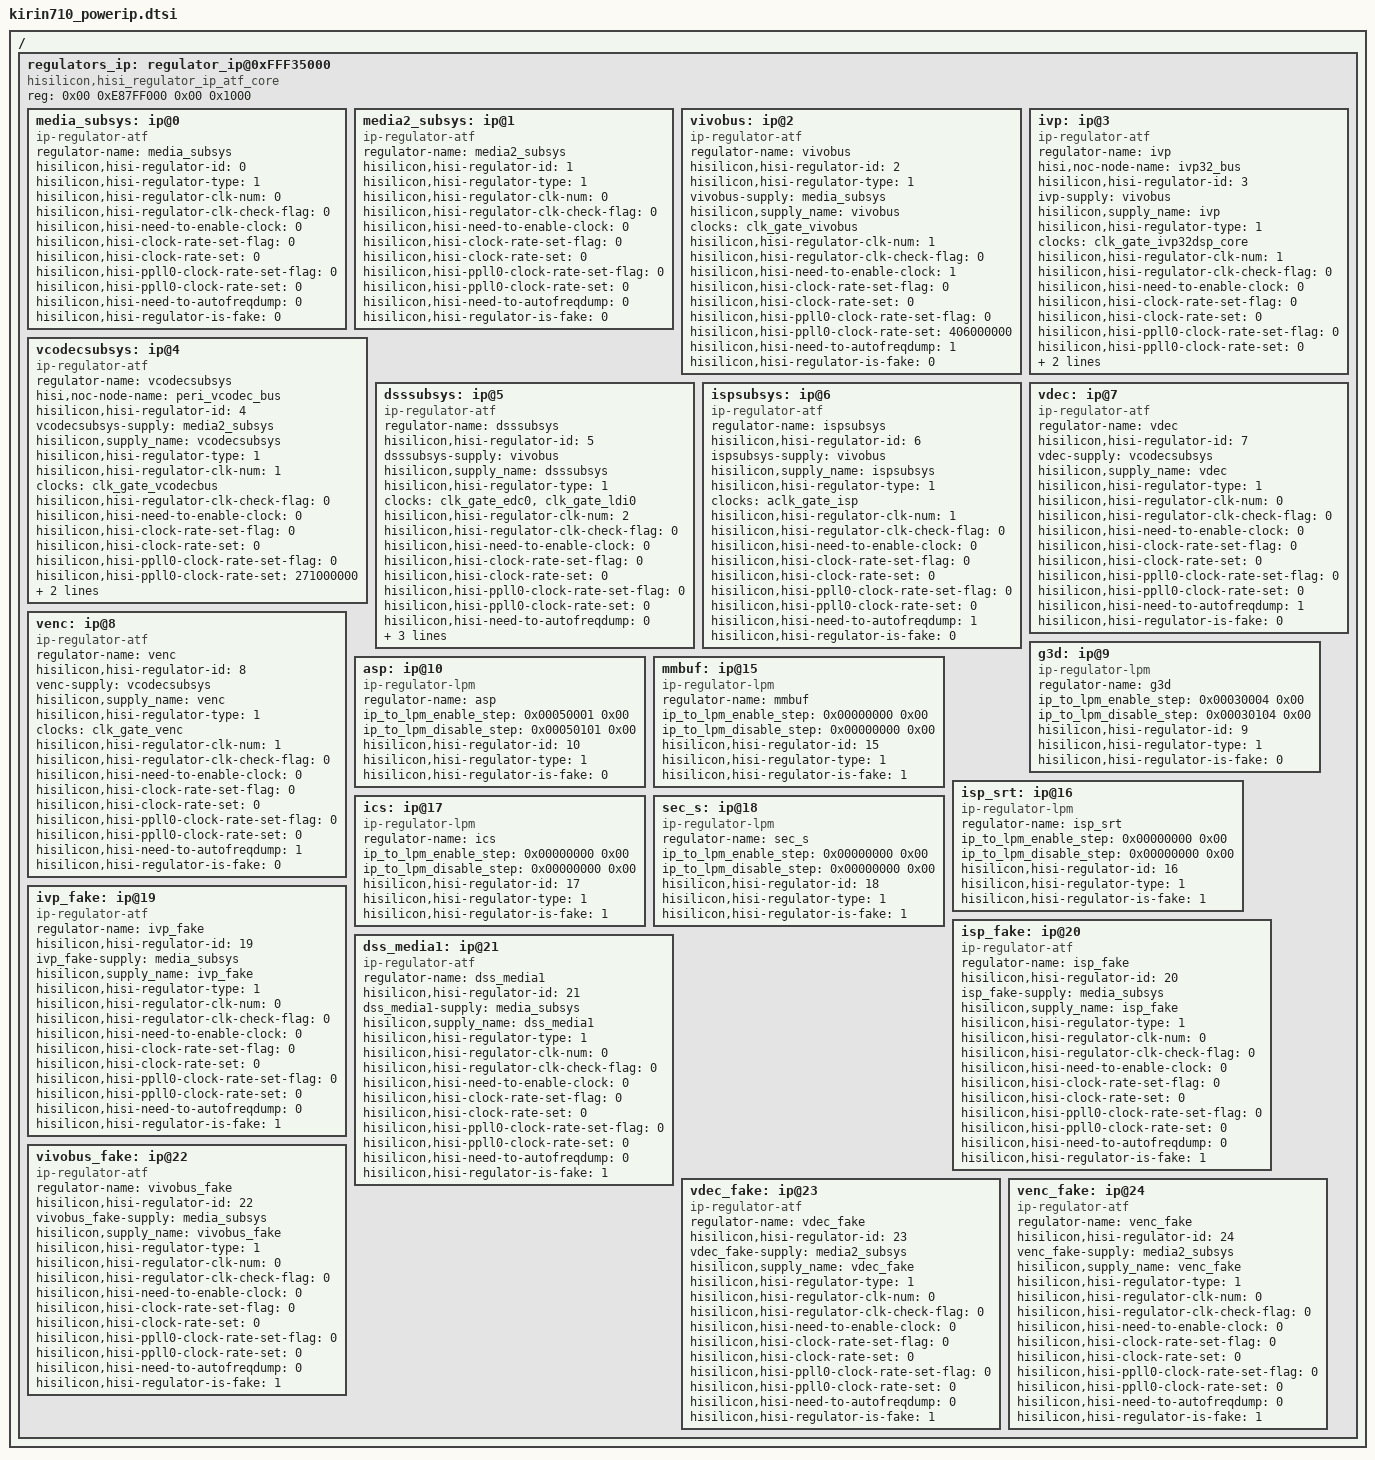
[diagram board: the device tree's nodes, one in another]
/*
 *  Copyright (C) 2012-2013 Linaro Ltd.
 *
 *  This program is free software; you can redistribute it and/or modify
 *  it under the terms of the GNU General Public License version 2 as
 *  publishhed by the Free Software Foundation.
 */

/ {
	regulators_ip: regulator_ip@0xFFF35000 {
		compatible = "hisilicon,hisi_regulator_ip_atf_core";
		reg = <0x00 0xE87FF000 0x00 0x1000>;

		media_subsys: ip@0 {
			compatible = "ip-regulator-atf";
			regulator-name = "media_subsys";
			hisilicon,hisi-regulator-id = <0>;
			hisilicon,hisi-regulator-type = <1>;/*0:pmu;1:ip;2:scharger*/
			hisilicon,hisi-regulator-clk-num = <0>;
			hisilicon,hisi-regulator-clk-check-flag = <0>;/*0:not check clock state;1:check clock state*/
			hisilicon,hisi-need-to-enable-clock = <0>;/*0:donot enable clock;1:enable clock*/
			hisilicon,hisi-clock-rate-set-flag = <0>;/*low frequency clock set flag:0:donot set clock rate;1:set clock rate*/
			hisilicon,hisi-clock-rate-set = <0>;/*frequency:0:not set frequency;*/
			hisilicon,hisi-ppll0-clock-rate-set-flag = <0>;/*switch to ppll0 flag:0:donot set clock rate;1:set clock rate*/
			hisilicon,hisi-ppll0-clock-rate-set = <0>;/*ppll0 frequency:0:not set frequency;*/
			hisilicon,hisi-need-to-autofreqdump = <0>;/*0:not need enale autofreqdump;1:need autofreqdump*/
			hisilicon,hisi-regulator-is-fake = <0>;/*0:this ip is effective;1:this ip is ineffective*/
		};

		media2_subsys: ip@1 {
			compatible = "ip-regulator-atf";
			regulator-name = "media2_subsys";
			hisilicon,hisi-regulator-id = <1>;
			hisilicon,hisi-regulator-type = <1>;
			hisilicon,hisi-regulator-clk-num = <0>;
			hisilicon,hisi-regulator-clk-check-flag = <0>;
			hisilicon,hisi-need-to-enable-clock = <0>;
			hisilicon,hisi-clock-rate-set-flag = <0>;
			hisilicon,hisi-clock-rate-set = <0>;
			hisilicon,hisi-ppll0-clock-rate-set-flag = <0>;
			hisilicon,hisi-ppll0-clock-rate-set = <0>;
			hisilicon,hisi-need-to-autofreqdump = <0>;
			hisilicon,hisi-regulator-is-fake = <0>;
		};

		vivobus: ip@2 {
			compatible = "ip-regulator-atf";
			regulator-name = "vivobus";
			hisilicon,hisi-regulator-id = <2>;
			hisilicon,hisi-regulator-type = <1>;/*0:pmu;1:ip;2:scharger*/
			vivobus-supply = <&media_subsys>;
			hisilicon,supply_name = "vivobus";
			clocks = <&clk_gate_vivobus>;
			clock-names = "clk_vivobus";
			hisilicon,hisi-regulator-clk-num = <1>;
			hisilicon,hisi-regulator-clk-check-flag = <0>;/*0:not check clock state;1:check clock state*/
			hisilicon,hisi-need-to-enable-clock = <1>;/*0:donot enable clock;1:enable clock*/
			hisilicon,hisi-clock-rate-set-flag = <0>;/*low frequency clock set flag:0:donot set clock rate;1:set clock rate*/
			hisilicon,hisi-clock-rate-set = <0>;/*frequency:0:not set frequency;*/
			hisilicon,hisi-ppll0-clock-rate-set-flag = <0>;
			hisilicon,hisi-ppll0-clock-rate-set = <406000000>;
			hisilicon,hisi-need-to-autofreqdump = <1>;/*0:not need enale autofreqdump;1:need autofreqdump*/
			hisilicon,hisi-regulator-is-fake = <0>;/*0:this ip is effective;1:this ip is ineffective*/
		};

		ivp: ip@3 {
			compatible = "ip-regulator-atf";
			regulator-name = "ivp";
			hisi,noc-node-name = "ivp32_bus";
			hisilicon,hisi-regulator-id = <3>;
			ivp-supply = <&vivobus>;
			hisilicon,supply_name = "ivp";
			hisilicon,hisi-regulator-type = <1>;
			clocks = <&clk_gate_ivp32dsp_core>;
			clock-names = "clk_ivpdsp_core";
			hisilicon,hisi-regulator-clk-num = <1>;
			hisilicon,hisi-regulator-clk-check-flag = <0>;
			hisilicon,hisi-need-to-enable-clock = <0>;
			hisilicon,hisi-clock-rate-set-flag = <0>;
			hisilicon,hisi-clock-rate-set = <0>;
			hisilicon,hisi-ppll0-clock-rate-set-flag = <0>;
			hisilicon,hisi-ppll0-clock-rate-set = <0>;
			hisilicon,hisi-need-to-autofreqdump = <1>;
			hisilicon,hisi-regulator-is-fake = <0>;
		};

		vcodecsubsys: ip@4 {
			compatible = "ip-regulator-atf";
			regulator-name = "vcodecsubsys";
			hisi,noc-node-name = "peri_vcodec_bus";
			hisilicon,hisi-regulator-id = <4>;
			vcodecsubsys-supply = <&media2_subsys>;
			hisilicon,supply_name = "vcodecsubsys";
			hisilicon,hisi-regulator-type = <1>;
			hisilicon,hisi-regulator-clk-num = <1>;
			clocks = <&clk_gate_vcodecbus>;
			clock-names = "clk_vcodecbus";
			hisilicon,hisi-regulator-clk-check-flag = <0>;
			hisilicon,hisi-need-to-enable-clock = <0>;
			hisilicon,hisi-clock-rate-set-flag = <0>;
			hisilicon,hisi-clock-rate-set = <0>;
			hisilicon,hisi-ppll0-clock-rate-set-flag = <0>;
			hisilicon,hisi-ppll0-clock-rate-set = <271000000>;
			hisilicon,hisi-need-to-autofreqdump = <1>;
			hisilicon,hisi-regulator-is-fake = <0>;
		};

		dsssubsys: ip@5 {
			compatible = "ip-regulator-atf";
			regulator-name = "dsssubsys";
			hisilicon,hisi-regulator-id = <5>;
			dsssubsys-supply = <&vivobus>;
			hisilicon,supply_name = "dsssubsys";
			hisilicon,hisi-regulator-type = <1>;
			clocks = <&clk_gate_edc0 &clk_gate_ldi0>;
			clock-names = "clk_edc0", "clk_ldi0";
			hisilicon,hisi-regulator-clk-num = <2>;
			hisilicon,hisi-regulator-clk-check-flag = <0>;
			hisilicon,hisi-need-to-enable-clock = <0>;
			hisilicon,hisi-clock-rate-set-flag = <0>;
			hisilicon,hisi-clock-rate-set = <0>;
			hisilicon,hisi-ppll0-clock-rate-set-flag = <0>;
			hisilicon,hisi-ppll0-clock-rate-set = <0>;
			hisilicon,hisi-need-to-autofreqdump = <0>;
			hisilicon,hisi-regulator-is-fake = <0>;
			hisilicon,hisi-regulator-dss-boot-check = <0x38 0xC0>;
		};
		ispsubsys: ip@6 {
			compatible = "ip-regulator-atf";
			regulator-name = "ispsubsys";
			hisilicon,hisi-regulator-id = <6>;
			ispsubsys-supply = <&vivobus>;
			hisilicon,supply_name = "ispsubsys";
			hisilicon,hisi-regulator-type = <1>;
			clocks = <&aclk_gate_isp>;
			clock-names = "aclk_isp";
			hisilicon,hisi-regulator-clk-num = <1>;
			hisilicon,hisi-regulator-clk-check-flag = <0>;
			hisilicon,hisi-need-to-enable-clock = <0>;
			hisilicon,hisi-clock-rate-set-flag = <0>;
			hisilicon,hisi-clock-rate-set = <0>;
			hisilicon,hisi-ppll0-clock-rate-set-flag = <0>;
			hisilicon,hisi-ppll0-clock-rate-set = <0>;
			hisilicon,hisi-need-to-autofreqdump = <1>;
			hisilicon,hisi-regulator-is-fake = <0>;
		};
		vdec: ip@7 {
			compatible = "ip-regulator-atf";
			regulator-name = "vdec";
			hisilicon,hisi-regulator-id = <7>;
			vdec-supply = <&vcodecsubsys>;
			hisilicon,supply_name = "vdec";
			hisilicon,hisi-regulator-type = <1>;
			hisilicon,hisi-regulator-clk-num = <0>;
			hisilicon,hisi-regulator-clk-check-flag = <0>;
			hisilicon,hisi-need-to-enable-clock = <0>;
			hisilicon,hisi-clock-rate-set-flag = <0>;
			hisilicon,hisi-clock-rate-set = <0>;
			hisilicon,hisi-ppll0-clock-rate-set-flag = <0>;
			hisilicon,hisi-ppll0-clock-rate-set = <0>;
			hisilicon,hisi-need-to-autofreqdump = <1>;
			hisilicon,hisi-regulator-is-fake = <0>;
		};
		venc: ip@8 {
			compatible = "ip-regulator-atf";
			regulator-name = "venc";
			hisilicon,hisi-regulator-id = <8>;
			venc-supply = <&vcodecsubsys>;
			hisilicon,supply_name = "venc";
			hisilicon,hisi-regulator-type = <1>;
			clocks = <&clk_gate_venc>;
			clock-names = "clk_venc";
			hisilicon,hisi-regulator-clk-num = <1>;
			hisilicon,hisi-regulator-clk-check-flag = <0>;
			hisilicon,hisi-need-to-enable-clock = <0>;
			hisilicon,hisi-clock-rate-set-flag = <0>;
			hisilicon,hisi-clock-rate-set = <0>;
			hisilicon,hisi-ppll0-clock-rate-set-flag = <0>;
			hisilicon,hisi-ppll0-clock-rate-set = <0>;
			hisilicon,hisi-need-to-autofreqdump = <1>;
			hisilicon,hisi-regulator-is-fake = <0>;
		};

		g3d: ip@9 {
			compatible = "ip-regulator-lpm";
			regulator-name = "g3d";
			ip_to_lpm_enable_step = <0x00030004 0x00>;
			ip_to_lpm_disable_step = <0x00030104 0x00>;
			hisilicon,hisi-regulator-id = <9>;
			hisilicon,hisi-regulator-type = <1>;
			hisilicon,hisi-regulator-is-fake = <0>;
		};
		asp: ip@10 {
			compatible = "ip-regulator-lpm";
			regulator-name = "asp";
			ip_to_lpm_enable_step = <0x00050001 0x00>;
			ip_to_lpm_disable_step = <0x00050101 0x00>;
			hisilicon,hisi-regulator-id = <10>;
			hisilicon,hisi-regulator-type = <1>;
			hisilicon,hisi-regulator-is-fake = <0>;
		};

		mmbuf: ip@15 {
			compatible = "ip-regulator-lpm";
			regulator-name = "mmbuf";
			ip_to_lpm_enable_step = <0x00000000 0x00>;
			ip_to_lpm_disable_step = <0x00000000 0x00>;
			hisilicon,hisi-regulator-id = <15>;
			hisilicon,hisi-regulator-type = <1>;
			hisilicon,hisi-regulator-is-fake = <1>;
		};
		isp_srt: ip@16 {
			compatible = "ip-regulator-lpm";
			regulator-name = "isp_srt";
			ip_to_lpm_enable_step = <0x00000000 0x00>;
			ip_to_lpm_disable_step = <0x00000000 0x00>;
			hisilicon,hisi-regulator-id = <16>;
			hisilicon,hisi-regulator-type = <1>;
			hisilicon,hisi-regulator-is-fake = <1>;
		};
		ics: ip@17 {
			compatible = "ip-regulator-lpm";
			regulator-name = "ics";
			ip_to_lpm_enable_step = <0x00000000 0x00>;
			ip_to_lpm_disable_step = <0x00000000 0x00>;
			hisilicon,hisi-regulator-id = <17>;
			hisilicon,hisi-regulator-type = <1>;
			hisilicon,hisi-regulator-is-fake = <1>;
		};
		sec_s: ip@18 {
			compatible = "ip-regulator-lpm";
			regulator-name = "sec_s";
			ip_to_lpm_enable_step = <0x00000000 0x00>;
			ip_to_lpm_disable_step = <0x00000000 0x00>;
			hisilicon,hisi-regulator-id = <18>;
			hisilicon,hisi-regulator-type = <1>;
			hisilicon,hisi-regulator-is-fake = <1>;
		};
		ivp_fake: ip@19 {
			compatible = "ip-regulator-atf";
			regulator-name = "ivp_fake";
			hisilicon,hisi-regulator-id = <19>;
			ivp_fake-supply = <&media_subsys>;
			hisilicon,supply_name = "ivp_fake";
			hisilicon,hisi-regulator-type = <1>;
			hisilicon,hisi-regulator-clk-num = <0>;
			hisilicon,hisi-regulator-clk-check-flag = <0>;
			hisilicon,hisi-need-to-enable-clock = <0>;
			hisilicon,hisi-clock-rate-set-flag = <0>;
			hisilicon,hisi-clock-rate-set = <0>;
			hisilicon,hisi-ppll0-clock-rate-set-flag = <0>;
			hisilicon,hisi-ppll0-clock-rate-set = <0>;
			hisilicon,hisi-need-to-autofreqdump = <0>;
			hisilicon,hisi-regulator-is-fake = <1>;
		};
		isp_fake: ip@20 {
			compatible = "ip-regulator-atf";
			regulator-name = "isp_fake";
			hisilicon,hisi-regulator-id = <20>;
			isp_fake-supply = <&media_subsys>;
			hisilicon,supply_name = "isp_fake";
			hisilicon,hisi-regulator-type = <1>;
			hisilicon,hisi-regulator-clk-num = <0>;
			hisilicon,hisi-regulator-clk-check-flag = <0>;
			hisilicon,hisi-need-to-enable-clock = <0>;
			hisilicon,hisi-clock-rate-set-flag = <0>;
			hisilicon,hisi-clock-rate-set = <0>;
			hisilicon,hisi-ppll0-clock-rate-set-flag = <0>;
			hisilicon,hisi-ppll0-clock-rate-set = <0>;
			hisilicon,hisi-need-to-autofreqdump = <0>;
			hisilicon,hisi-regulator-is-fake = <1>;
		};
		dss_media1: ip@21 {
			compatible = "ip-regulator-atf";
			regulator-name = "dss_media1";
			hisilicon,hisi-regulator-id = <21>;
			dss_media1-supply = <&media_subsys>;
			hisilicon,supply_name = "dss_media1";
			hisilicon,hisi-regulator-type = <1>;
			hisilicon,hisi-regulator-clk-num = <0>;
			hisilicon,hisi-regulator-clk-check-flag = <0>;
			hisilicon,hisi-need-to-enable-clock = <0>;
			hisilicon,hisi-clock-rate-set-flag = <0>;
			hisilicon,hisi-clock-rate-set = <0>;
			hisilicon,hisi-ppll0-clock-rate-set-flag = <0>;
			hisilicon,hisi-ppll0-clock-rate-set = <0>;
			hisilicon,hisi-need-to-autofreqdump = <0>;
			hisilicon,hisi-regulator-is-fake = <1>;
		};
		vivobus_fake: ip@22 {
			compatible = "ip-regulator-atf";
			regulator-name = "vivobus_fake";
			hisilicon,hisi-regulator-id = <22>;
			vivobus_fake-supply = <&media_subsys>;
			hisilicon,supply_name = "vivobus_fake";
			hisilicon,hisi-regulator-type = <1>;
			hisilicon,hisi-regulator-clk-num = <0>;
			hisilicon,hisi-regulator-clk-check-flag = <0>;
			hisilicon,hisi-need-to-enable-clock = <0>;
			hisilicon,hisi-clock-rate-set-flag = <0>;
			hisilicon,hisi-clock-rate-set = <0>;
			hisilicon,hisi-ppll0-clock-rate-set-flag = <0>;
			hisilicon,hisi-ppll0-clock-rate-set = <0>;
			hisilicon,hisi-need-to-autofreqdump = <0>;
			hisilicon,hisi-regulator-is-fake = <1>;
		};
		vdec_fake: ip@23 {
			compatible = "ip-regulator-atf";
			regulator-name = "vdec_fake";
			hisilicon,hisi-regulator-id = <23>;
			vdec_fake-supply = <&media2_subsys>;
			hisilicon,supply_name = "vdec_fake";
			hisilicon,hisi-regulator-type = <1>;
			hisilicon,hisi-regulator-clk-num = <0>;
			hisilicon,hisi-regulator-clk-check-flag = <0>;
			hisilicon,hisi-need-to-enable-clock = <0>;
			hisilicon,hisi-clock-rate-set-flag = <0>;
			hisilicon,hisi-clock-rate-set = <0>;
			hisilicon,hisi-ppll0-clock-rate-set-flag = <0>;
			hisilicon,hisi-ppll0-clock-rate-set = <0>;
			hisilicon,hisi-need-to-autofreqdump = <0>;
			hisilicon,hisi-regulator-is-fake = <1>;
		};
		venc_fake: ip@24 {
			compatible = "ip-regulator-atf";
			regulator-name = "venc_fake";
			hisilicon,hisi-regulator-id = <24>;
			venc_fake-supply = <&media2_subsys>;
			hisilicon,supply_name = "venc_fake";
			hisilicon,hisi-regulator-type = <1>;
			hisilicon,hisi-regulator-clk-num = <0>;
			hisilicon,hisi-regulator-clk-check-flag = <0>;
			hisilicon,hisi-need-to-enable-clock = <0>;
			hisilicon,hisi-clock-rate-set-flag = <0>;
			hisilicon,hisi-clock-rate-set = <0>;
			hisilicon,hisi-ppll0-clock-rate-set-flag = <0>;
			hisilicon,hisi-ppll0-clock-rate-set = <0>;
			hisilicon,hisi-need-to-autofreqdump = <0>;
			hisilicon,hisi-regulator-is-fake = <1>;
		};
	};
};
